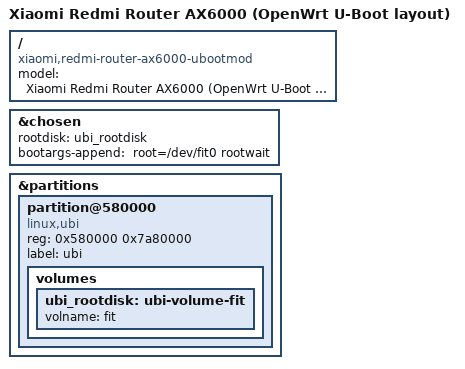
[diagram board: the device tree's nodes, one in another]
// SPDX-License-Identifier: (GPL-2.0 OR MIT)

/dts-v1/;
#include "mt7986a-xiaomi-redmi-router-ax6000.dtsi"

/ {
	model = "Xiaomi Redmi Router AX6000 (OpenWrt U-Boot layout)";
	compatible = "xiaomi,redmi-router-ax6000-ubootmod", "mediatek,mt7986a";
};

&chosen {
	rootdisk = <&ubi_rootdisk>;
	bootargs-append = " root=/dev/fit0 rootwait";
};

&partitions {
	partition@580000 {
		compatible = "linux,ubi";
		reg = <0x580000 0x7a80000>;
		label = "ubi";

		volumes {
			ubi_rootdisk: ubi-volume-fit {
				volname = "fit";
			};
		};
	};
};
